AUTOSAR XML (schema 4-1-3)
standard types defined: boolean, uint8
package /UAES/ASW/CompuMethods
  compu method CM_boolean: 0=FALSE, 1=TRUE
package /UAES/ASW/DataConstrs
  range DC_boolean: raw 0..1
  range DC_uint8: raw 0..255
package /UAES/ASW/DataTypeMappingSets
  data type mapping set DTMS_ElecDoorHndl_ComCnvRx
package /UAES/ASW/PortInterfaces
  6 x sender receiver interface:
    ComRx_bLCK_RearLeftDoorHandle: invalidation-policy{data-element=ComRx_bLCK_RearLeftDoorHandle/Val, handle-invalid=DONT-INVALIDATE}
      data Val: sw-calibration-access=READ-ONLY, type=boolean
    ComRx_bLCK_RearRightDoorHandle: invalidation-policy{data-element=ComRx_bLCK_RearRightDoorHandle/Val, handle-invalid=DONT-INVALIDATE}
      data Val: sw-calibration-access=READ-ONLY, type=boolean
    ComRx_u8LCK_DoorHandleCommandActionType: invalidation-policy{data-element=ComRx_u8LCK_DoorHandleCommandActionType/Val, handle-invalid=DONT-INVALIDATE}
      data Val: sw-calibration-access=READ-ONLY, type=uint8
    gCAN_bLCK_RearLeftDoorHandle: invalidation-policy{data-element=gCAN_bLCK_RearLeftDoorHandle/Val, handle-invalid=DONT-INVALIDATE}
      data Val: sw-calibration-access=READ-ONLY, type=boolean
    gCAN_bLCK_RearRightDoorHandle: invalidation-policy{data-element=gCAN_bLCK_RearRightDoorHandle/Val, handle-invalid=DONT-INVALIDATE}
      data Val: sw-calibration-access=READ-ONLY, type=boolean
    gCAN_u8LCK_DoorHandleCommandActionType: invalidation-policy{data-element=gCAN_u8LCK_DoorHandleCommandActionType/Val, handle-invalid=DONT-INVALIDATE}
      data Val: sw-calibration-access=READ-ONLY, type=uint8
package /UAES/ASW/SwComponentTypes
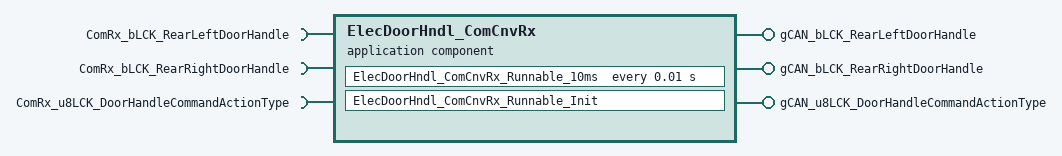
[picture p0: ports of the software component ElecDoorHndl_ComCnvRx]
  application sw component type ElecDoorHndl_ComCnvRx
    provide port gCAN_bLCK_RearLeftDoorHandle: nonqueued-sender-com-spec{data-element=gCAN_bLCK_RearLeftDoorHandle/Val, init-value=0}, provided-interface=gCAN_bLCK_RearLeftDoorHandle
    provide port gCAN_bLCK_RearRightDoorHandle: nonqueued-sender-com-spec{data-element=gCAN_bLCK_RearRightDoorHandle/Val, init-value=0}, provided-interface=gCAN_bLCK_RearRightDoorHandle
    provide port gCAN_u8LCK_DoorHandleCommandActionType: nonqueued-sender-com-spec{data-element=gCAN_u8LCK_DoorHandleCommandActionType/Val, init-value=0}, provided-interface=gCAN_u8LCK_DoorHandleCommandActionType
    require port ComRx_bLCK_RearLeftDoorHandle: nonqueued-receiver-com-spec{data-element=ComRx_bLCK_RearLeftDoorHandle/Val, filter=data-filter-type=ALWAYS, init-value=0}, required-interface=ComRx_bLCK_RearLeftDoorHandle
    require port ComRx_bLCK_RearRightDoorHandle: nonqueued-receiver-com-spec{data-element=ComRx_bLCK_RearRightDoorHandle/Val, filter=data-filter-type=ALWAYS, init-value=0}, required-interface=ComRx_bLCK_RearRightDoorHandle
    require port ComRx_u8LCK_DoorHandleCommandActionType: nonqueued-receiver-com-spec{data-element=ComRx_u8LCK_DoorHandleCommandActionType/Val, filter=data-filter-type=ALWAYS, init-value=0}, required-interface=ComRx_u8LCK_DoorHandleCommandActionType
    behavior ElecDoorHndl_ComCnvRx_InternalBehavior: data-type-mapping=DTMS_ElecDoorHndl_ComCnvRx
      timing event TMT_ElecDoorHndl_ComCnvRx_Runnable_10ms: start-on-event=ElecDoorHndl_ComCnvRx_Runnable_10ms, period=0.01
      init event ElecDoorHndl_ComCnvRx_InitEvent: start-on-event=ElecDoorHndl_ComCnvRx_Runnable_Init
      runnable ElecDoorHndl_ComCnvRx_Runnable_10ms
        data-receive-point-by-arguments:
          access REC_ComRx_bLCK_RearLeftDoorHandle_Val: accessed-variable=ComRx_bLCK_RearLeftDoorHandle.Val
          access REC_ComRx_bLCK_RearRightDoorHandle_Val: accessed-variable=ComRx_bLCK_RearRightDoorHandle.Val
          access REC_ComRx_u8LCK_DoorHandleCommandActionType_Val: accessed-variable=ComRx_u8LCK_DoorHandleCommandActionType.Val
        data-send-points:
          access SEND_gCAN_bLCK_RearLeftDoorHandle_Val: accessed-variable=gCAN_bLCK_RearLeftDoorHandle.Val
          access SEND_gCAN_bLCK_RearRightDoorHandle_Val: accessed-variable=gCAN_bLCK_RearRightDoorHandle.Val
          access SEND_gCAN_u8LCK_DoorHandleCommandActionType_Val: accessed-variable=gCAN_u8LCK_DoorHandleCommandActionType.Val
      runnable ElecDoorHndl_ComCnvRx_Runnable_Init
  swc implementation ElecDoorHndl_ComCnvRx_Implementation: behavior=ElecDoorHndl_ComCnvRx_InternalBehavior
    code-descriptors:
      code Default: artifact-descriptors=autosar-engineering-object={short-label=Default, category=SWSRC}
package /UAES/ASW/Units
  unit NoUnit: factor-si-to-unit=1, offset-si-to-unit=0
